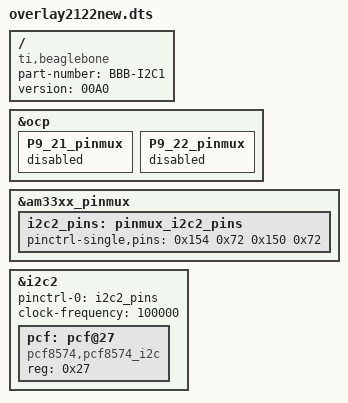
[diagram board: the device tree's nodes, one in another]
/dts-v1/;
/plugin/;

/ {
  compatible = "ti,beaglebone", "ti,beaglebone-black";
  part-number = "BBB-I2C1"; // memorable name
  version = "00A0";

  // New fragment to disable existing pin configuration
  fragment@0 {
    target = <&ocp>; // target the on-chip peripherals

    __overlay__ {
      // Disable the existing pin configurations
      P9_21_pinmux { status = "disabled"; };
      P9_22_pinmux { status = "disabled"; };
    };
  };

  fragment@1 {
    target = <&am33xx_pinmux>; // link to the main pinmux node

    __overlay__ {
      i2c2_pins: pinmux_i2c2_pins { // rename to i2c1_pins
        pinctrl-single,pins = <
          0x154 0x72 /* spi0_d1.i2c1_sda */
          0x150 0x72 /* spi0_cs0.i2c1_scl */
        >;
      };
    };
  };

  fragment@2 {
    target = <&i2c2>; // target I2C1 instead of I2C2

    __overlay__ {
      pinctrl-0 = <&i2c2_pins>;
      #address-cells = <1>;
      #size-cells = <0>;

      clock-frequency = <100000>;
      status = "okay";

      pcf: pcf@27 {
        compatible = "pcf8574,pcf8574_i2c";
        reg = <0x27>;
      };
    };
  };
};

